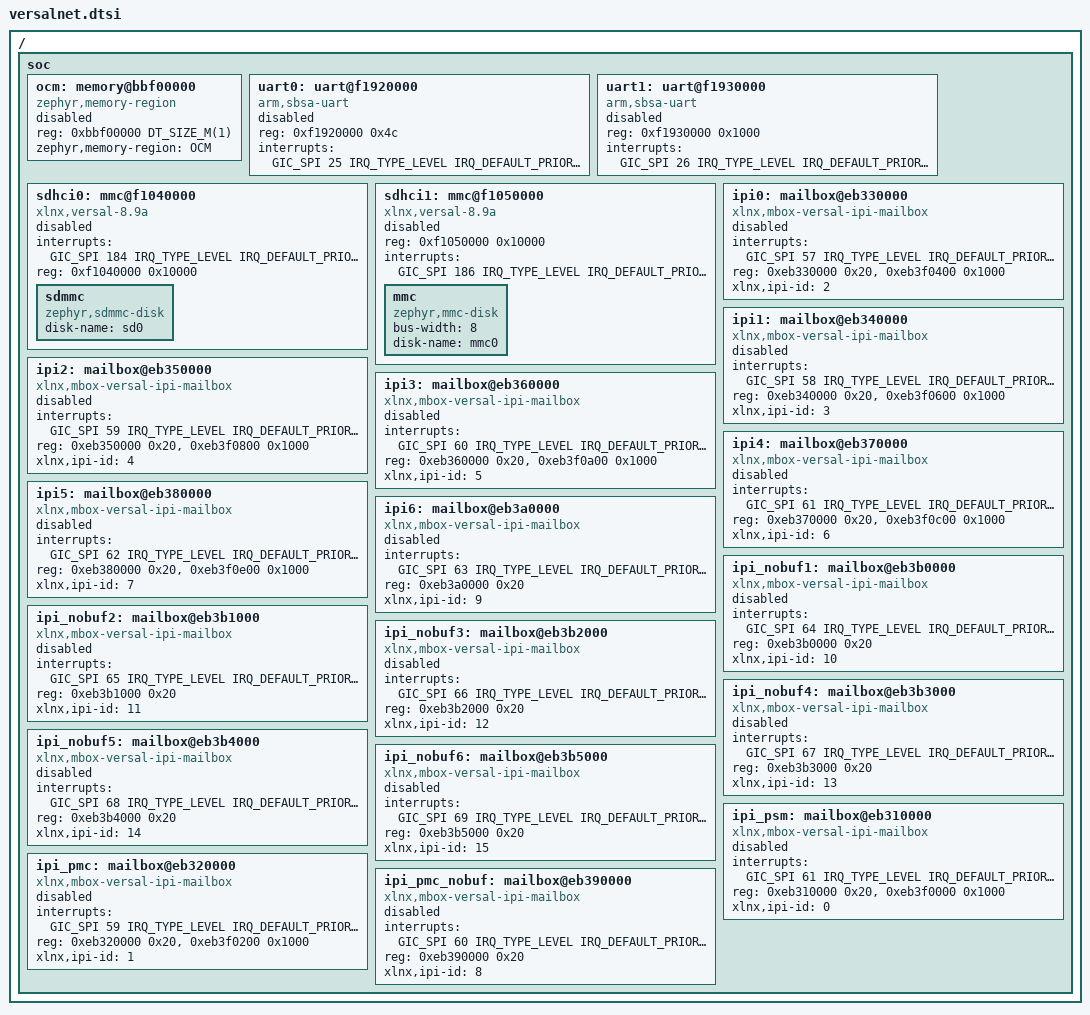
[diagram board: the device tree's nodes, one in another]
/*
 * Copyright (c) 2025, Advanced Micro Devices, Inc.
 *
 * SPDX-License-Identifier: Apache-2.0
 */

/ {
	soc: soc {
		ocm: memory@bbf00000 {
			compatible = "zephyr,memory-region";
			reg = <0xbbf00000 DT_SIZE_M(1)>;
			status = "disabled";
			zephyr,memory-region = "OCM";
		};

		uart0: uart@f1920000 {
			compatible = "arm,sbsa-uart";
			reg = <0xf1920000 0x4c>;
			status = "disabled";
			interrupt-names = "irq_0";
			interrupts = <GIC_SPI 25 IRQ_TYPE_LEVEL IRQ_DEFAULT_PRIORITY>;
		};

		uart1: uart@f1930000 {
			compatible = "arm,sbsa-uart";
			reg = <0xf1930000 0x1000>;
			status = "disabled";
			interrupt-names = "irq_1";
			interrupts = <GIC_SPI 26 IRQ_TYPE_LEVEL IRQ_DEFAULT_PRIORITY>;
		};

		sdhci0: mmc@f1040000 {
			compatible = "xlnx,versal-8.9a";
			status = "disabled";
			interrupts = <GIC_SPI 184 IRQ_TYPE_LEVEL IRQ_DEFAULT_PRIORITY>;
			reg = <0xf1040000 0x10000>;

			sdmmc {
				compatible = "zephyr,sdmmc-disk";
				disk-name = "sd0";
			};
		};

		sdhci1: mmc@f1050000 {
			compatible = "xlnx,versal-8.9a";
			status = "disabled";
			reg = <0xf1050000 0x10000>;
			interrupts = <GIC_SPI 186 IRQ_TYPE_LEVEL IRQ_DEFAULT_PRIORITY>;

			mmc {
				compatible = "zephyr,mmc-disk";
				bus-width = <8>;
				disk-name = "mmc0";
			};
		};

		ipi0: mailbox@eb330000 {
			compatible = "xlnx,mbox-versal-ipi-mailbox";
			status = "disabled";
			interrupts = <GIC_SPI 57 IRQ_TYPE_LEVEL IRQ_DEFAULT_PRIORITY>;
			reg = <0xeb330000 0x20>, <0xeb3f0400 0x1000>;
			reg-names = "ctrl", "msg";
			xlnx,ipi-id = <2>;
			#address-cells = <1>;
			#size-cells = <1>;
		};

		ipi1: mailbox@eb340000 {
			compatible = "xlnx,mbox-versal-ipi-mailbox";
			status = "disabled";
			interrupts = <GIC_SPI 58 IRQ_TYPE_LEVEL IRQ_DEFAULT_PRIORITY>;
			reg = <0xeb340000 0x20>, <0xeb3f0600 0x1000>;
			reg-names = "ctrl", "msg";
			xlnx,ipi-id = <3>;
			#address-cells = <1>;
			#size-cells = <1>;
		};

		ipi2: mailbox@eb350000 {
			compatible = "xlnx,mbox-versal-ipi-mailbox";
			status = "disabled";
			interrupts = <GIC_SPI 59 IRQ_TYPE_LEVEL IRQ_DEFAULT_PRIORITY>;
			reg = <0xeb350000 0x20>, <0xeb3f0800 0x1000>;
			reg-names = "ctrl", "msg";
			xlnx,ipi-id = <4>;
			#address-cells = <1>;
			#size-cells = <1>;
		};

		ipi3: mailbox@eb360000 {
			compatible = "xlnx,mbox-versal-ipi-mailbox";
			status = "disabled";
			interrupts = <GIC_SPI 60 IRQ_TYPE_LEVEL IRQ_DEFAULT_PRIORITY>;
			reg = <0xeb360000 0x20>, <0xeb3f0a00 0x1000>;
			reg-names = "ctrl", "msg";
			xlnx,ipi-id = <5>;
			#address-cells = <1>;
			#size-cells = <1>;
		};

		ipi4: mailbox@eb370000 {
			compatible = "xlnx,mbox-versal-ipi-mailbox";
			status = "disabled";
			interrupts = <GIC_SPI 61 IRQ_TYPE_LEVEL IRQ_DEFAULT_PRIORITY>;
			reg = <0xeb370000 0x20>, <0xeb3f0c00 0x1000>;
			reg-names = "ctrl", "msg";
			xlnx,ipi-id = <6>;
			#address-cells = <1>;
			#size-cells = <1>;
		};

		ipi5: mailbox@eb380000 {
			compatible = "xlnx,mbox-versal-ipi-mailbox";
			status = "disabled";
			interrupts = <GIC_SPI 62 IRQ_TYPE_LEVEL IRQ_DEFAULT_PRIORITY>;
			reg = <0xeb380000 0x20>, <0xeb3f0e00 0x1000>;
			reg-names = "ctrl", "msg";
			xlnx,ipi-id = <7>;
			#address-cells = <1>;
			#size-cells = <1>;
		};

		ipi6: mailbox@eb3a0000 {
			compatible = "xlnx,mbox-versal-ipi-mailbox";
			status = "disabled";
			interrupts = <GIC_SPI 63 IRQ_TYPE_LEVEL IRQ_DEFAULT_PRIORITY>;
			reg = <0xeb3a0000 0x20>;
			reg-names = "ctrl";
			xlnx,ipi-id = <9>;
			#address-cells = <1>;
			#size-cells = <1>;
		};

		ipi_nobuf1: mailbox@eb3b0000 {
			compatible = "xlnx,mbox-versal-ipi-mailbox";
			status = "disabled";
			interrupts = <GIC_SPI 64 IRQ_TYPE_LEVEL IRQ_DEFAULT_PRIORITY>;
			reg = <0xeb3b0000 0x20>;
			reg-names = "ctrl";
			xlnx,ipi-id = <10>;
			#address-cells = <1>;
			#size-cells = <1>;
		};

		ipi_nobuf2: mailbox@eb3b1000 {
			compatible = "xlnx,mbox-versal-ipi-mailbox";
			status = "disabled";
			interrupts = <GIC_SPI 65 IRQ_TYPE_LEVEL IRQ_DEFAULT_PRIORITY>;
			reg = <0xeb3b1000 0x20>;
			reg-names = "ctrl";
			xlnx,ipi-id = <11>;
			#address-cells = <1>;
			#size-cells = <1>;
		};

		ipi_nobuf3: mailbox@eb3b2000 {
			compatible = "xlnx,mbox-versal-ipi-mailbox";
			status = "disabled";
			interrupts = <GIC_SPI 66 IRQ_TYPE_LEVEL IRQ_DEFAULT_PRIORITY>;
			reg = <0xeb3b2000 0x20>;
			reg-names = "ctrl";
			xlnx,ipi-id = <12>;
			#address-cells = <1>;
			#size-cells = <1>;
		};

		ipi_nobuf4: mailbox@eb3b3000 {
			compatible = "xlnx,mbox-versal-ipi-mailbox";
			status = "disabled";
			interrupts = <GIC_SPI 67 IRQ_TYPE_LEVEL IRQ_DEFAULT_PRIORITY>;
			reg = <0xeb3b3000 0x20>;
			reg-names = "ctrl";
			xlnx,ipi-id = <13>;
			#address-cells = <1>;
			#size-cells = <1>;
		};

		ipi_nobuf5: mailbox@eb3b4000 {
			compatible = "xlnx,mbox-versal-ipi-mailbox";
			status = "disabled";
			interrupts = <GIC_SPI 68 IRQ_TYPE_LEVEL IRQ_DEFAULT_PRIORITY>;
			reg = <0xeb3b4000 0x20>;
			reg-names = "ctrl";
			xlnx,ipi-id = <14>;
			#address-cells = <1>;
			#size-cells = <1>;
		};

		ipi_nobuf6: mailbox@eb3b5000 {
			compatible = "xlnx,mbox-versal-ipi-mailbox";
			status = "disabled";
			interrupts = <GIC_SPI 69 IRQ_TYPE_LEVEL IRQ_DEFAULT_PRIORITY>;
			reg = <0xeb3b5000 0x20>;
			reg-names = "ctrl";
			xlnx,ipi-id = <15>;
			#address-cells = <1>;
			#size-cells = <1>;
		};

		ipi_psm: mailbox@eb310000 {
			compatible = "xlnx,mbox-versal-ipi-mailbox";
			status = "disabled";
			interrupts = <GIC_SPI 61 IRQ_TYPE_LEVEL IRQ_DEFAULT_PRIORITY>;
			reg = <0xeb310000 0x20>, <0xeb3f0000 0x1000>;
			reg-names = "ctrl", "msg";
			xlnx,ipi-id = <0>;
			#address-cells = <1>;
			#size-cells = <1>;
		};

		ipi_pmc: mailbox@eb320000 {
			compatible = "xlnx,mbox-versal-ipi-mailbox";
			status = "disabled";
			interrupts = <GIC_SPI 59 IRQ_TYPE_LEVEL IRQ_DEFAULT_PRIORITY>;
			reg = <0xeb320000 0x20>, <0xeb3f0200 0x1000>;
			reg-names = "ctrl", "msg";
			xlnx,ipi-id = <1>;
			#address-cells = <1>;
			#size-cells = <1>;
		};

		ipi_pmc_nobuf: mailbox@eb390000 {
			compatible = "xlnx,mbox-versal-ipi-mailbox";
			status = "disabled";
			interrupts = <GIC_SPI 60 IRQ_TYPE_LEVEL IRQ_DEFAULT_PRIORITY>;
			reg = <0xeb390000 0x20>;
			reg-names = "ctrl";
			xlnx,ipi-id = <8>;
			#address-cells = <1>;
			#size-cells = <1>;
		};
	};
};
